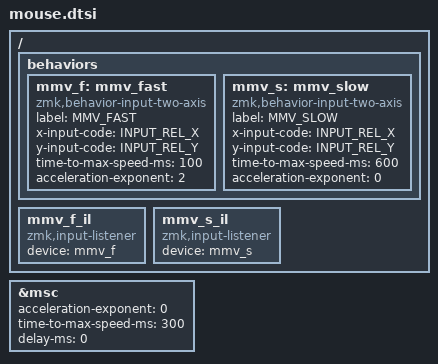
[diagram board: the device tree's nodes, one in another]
/*
 * Mouse Layer Configuration
 * Fast (left hand) vs Slow/Precision (right hand)
 */

#define ZMK_POINTING_DEFAULT_MOVE_VAL 600
#define ZMK_POINTING_DEFAULT_SCRL_VAL 20

#include <dt-bindings/zmk/pointing.h>

// Scroll settings - linear for precision
&msc {
    acceleration-exponent = <0>;
    time-to-max-speed-ms = <300>;
    delay-ms = <0>;
};

// Fast movement values (2400 = 4x base speed)
// Format: (value << 16) | axis where axis: 0=horiz, 1=vert
#define MOVE_F_UP    0x09600001
#define MOVE_F_DOWN  0xF6A00001
#define MOVE_F_LEFT  0xF6A00000
#define MOVE_F_RIGHT 0x09600000

/ {
    behaviors {
        // Fast mouse - 4x velocity, quick acceleration
        mmv_f: mmv_fast {
            compatible = "zmk,behavior-input-two-axis";
            label = "MMV_FAST";
            #binding-cells = <1>;
            x-input-code = <INPUT_REL_X>;
            y-input-code = <INPUT_REL_Y>;
            time-to-max-speed-ms = <100>;
            acceleration-exponent = <2>;
        };

        // Slow mouse - base velocity, no acceleration for precision
        mmv_s: mmv_slow {
            compatible = "zmk,behavior-input-two-axis";
            label = "MMV_SLOW";
            #binding-cells = <1>;
            x-input-code = <INPUT_REL_X>;
            y-input-code = <INPUT_REL_Y>;
            time-to-max-speed-ms = <600>;
            acceleration-exponent = <0>;
        };
    };

    // Input listeners - required for behaviors to work
    mmv_f_il { compatible = "zmk,input-listener"; device = <&mmv_f>; };
    mmv_s_il { compatible = "zmk,input-listener"; device = <&mmv_s>; };
};

// Scroll macros (standard direction)
#define U_WH_U &msc SCRL_UP
#define U_WH_D &msc SCRL_DOWN
#define U_WH_L &msc SCRL_LEFT
#define U_WH_R &msc SCRL_RIGHT
